# CY8C5888LTI_LP097 register map
File version: 0.1
CY8C58LP
Registers are 8-bit, read-write, no defined reset value unless marked. A register's access mark holds for its fields unless they carry their own. Offsets are from the block's base; lines under a group give offsets from that group; [hi:lo] are bit positions; {n}, {i} and the like mark numbered series; 'fields as' and 'values as' point back to an identical list; <NAME> marks a mode.

## Memory map
0x00000000 QuadDec_1
0x00000000 QuadDec_1_Cnt8
0x00000000 QuadDec_2
0x00000000 QuadDec_2_Cnt8
0x00000000 TimeOutResetReg
0x00000000 LightSens2_TimeOut
0x00000000 LightSens1_TimeOut

## QuadDec_1
Base 0x00000000
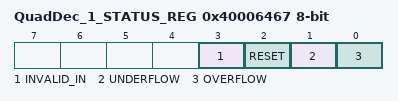
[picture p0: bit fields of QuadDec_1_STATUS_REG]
0x40006467 QuadDec_1_STATUS_REG — Quadrature Decoder Status Register
  [3] INVALID_IN ro — Invalid state transition on the A and B inputs
  [2] RESET ro — Counter Reset due index
  [1] UNDERFLOW ro — Counter underflow
  [0] OVERFLOW ro — Counter overflow
0x40006506 QuadDec_1_Cnt8_COUNTER — Counter value

## QuadDec_1_Cnt8
Base 0x00000000; alternate view of QuadDec_1
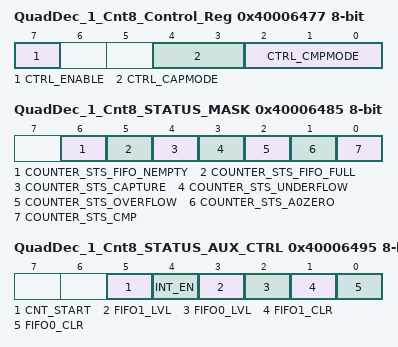
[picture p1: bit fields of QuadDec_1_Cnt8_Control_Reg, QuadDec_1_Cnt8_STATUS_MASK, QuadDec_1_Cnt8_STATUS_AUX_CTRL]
0x40006477 QuadDec_1_Cnt8_Control_Reg — UDB Control Register - Assigned Control Register Value
  [7] CTRL_ENABLE — Enable Counter
  [4:3] CTRL_CAPMODE — Capture mode
  [2:0] CTRL_CMPMODE — Compare mode
0x40006485 QuadDec_1_Cnt8_STATUS_MASK — UDB Status bits Interrupt Mask Enable Register
  [6] COUNTER_STS_FIFO_NEMPTY — FIFO Not Empty Status
  [5] COUNTER_STS_FIFO_FULL — FIFO Full Status
  [4] COUNTER_STS_CAPTURE — Capture Status
  [3] COUNTER_STS_UNDERFLOW — Underflow status
  [2] COUNTER_STS_OVERFLOW — Overflow status
  [1] COUNTER_STS_A0ZERO — A0 Zero ouput status
  [0] COUNTER_STS_CMP — Compare output status
0x40006495 QuadDec_1_Cnt8_STATUS_AUX_CTRL — UDB Auxilliary Control Register
  [5] CNT_START — FIFO0 clear
    0=E_CNT_START0 (Disable counter); 1=E_CNT_START1 (Enable counter)
  [4] INT_EN
    0=E_INT_EN0 (Interrupt disabled); 1=E_INT_EN1 (Interrupt enabled)
  [3] FIFO1_LVL — FIFO level
    0=E_FIFO_LVL_0 (FIFO LVL: input mode: FIFO not full; output mode: FIFO not empty); 1=E_FIFO_LVL_1 (FIFO LVL: input mode: FIFO at least 1/2 empty; output mode: FIFO at least 1/2 full)
  [2] FIFO0_LVL — FIFO level
    values as FIFO1_LVL
  [1] FIFO1_CLR — FIFO1 clear
    0=E_FIFO_CLR_0 (Normal FIFO operation); 1=E_FIFO_CLR_1 (Clear FIFO state)
  [0] FIFO0_CLR — FIFO0 clear
    values as FIFO1_CLR
0x40006506 QuadDec_1_Cnt8_COUNTER — UDB.A0 - Current Counter Value
0x40006526 QuadDec_1_Cnt8_PERIOD — UDB.D0 - Assigned Period
0x40006536 QuadDec_1_Cnt8_COMPARE — UDB.D1 - Assigned Compare Value

## QuadDec_2
Base 0x00000000
0x40006400 QuadDec_2_Cnt8_COUNTER — Counter value
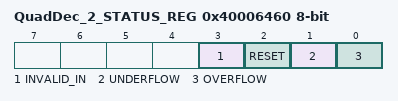
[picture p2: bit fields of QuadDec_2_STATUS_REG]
0x40006460 QuadDec_2_STATUS_REG — Quadrature Decoder Status Register
  [3] INVALID_IN ro — Invalid state transition on the A and B inputs
  [2] RESET ro — Counter Reset due index
  [1] UNDERFLOW ro — Counter underflow
  [0] OVERFLOW ro — Counter overflow

## QuadDec_2_Cnt8
Base 0x00000000; alternate view of QuadDec_2
0x40006400 QuadDec_2_Cnt8_COUNTER — UDB.A0 - Current Counter Value
0x40006420 QuadDec_2_Cnt8_PERIOD — UDB.D0 - Assigned Period
0x40006430 QuadDec_2_Cnt8_COMPARE — UDB.D1 - Assigned Compare Value
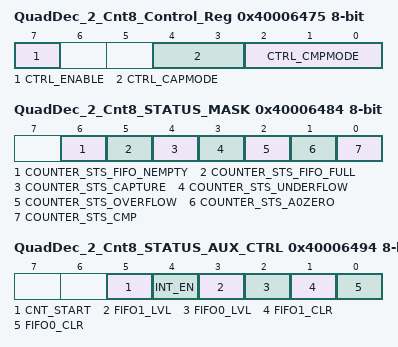
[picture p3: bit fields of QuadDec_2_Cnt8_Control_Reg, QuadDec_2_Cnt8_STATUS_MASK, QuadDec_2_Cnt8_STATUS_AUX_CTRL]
0x40006475 QuadDec_2_Cnt8_Control_Reg — UDB Control Register - Assigned Control Register Value
  [7] CTRL_ENABLE — Enable Counter
  [4:3] CTRL_CAPMODE — Capture mode
  [2:0] CTRL_CMPMODE — Compare mode
0x40006484 QuadDec_2_Cnt8_STATUS_MASK — UDB Status bits Interrupt Mask Enable Register
  [6] COUNTER_STS_FIFO_NEMPTY — FIFO Not Empty Status
  [5] COUNTER_STS_FIFO_FULL — FIFO Full Status
  [4] COUNTER_STS_CAPTURE — Capture Status
  [3] COUNTER_STS_UNDERFLOW — Underflow status
  [2] COUNTER_STS_OVERFLOW — Overflow status
  [1] COUNTER_STS_A0ZERO — A0 Zero ouput status
  [0] COUNTER_STS_CMP — Compare output status
0x40006494 QuadDec_2_Cnt8_STATUS_AUX_CTRL — UDB Auxilliary Control Register
  [5] CNT_START — FIFO0 clear
    0=E_CNT_START0 (Disable counter); 1=E_CNT_START1 (Enable counter)
  [4] INT_EN
    0=E_INT_EN0 (Interrupt disabled); 1=E_INT_EN1 (Interrupt enabled)
  [3] FIFO1_LVL — FIFO level
    0=E_FIFO_LVL_0 (FIFO LVL: input mode: FIFO not full; output mode: FIFO not empty); 1=E_FIFO_LVL_1 (FIFO LVL: input mode: FIFO at least 1/2 empty; output mode: FIFO at least 1/2 full)
  [2] FIFO0_LVL — FIFO level
    values as FIFO1_LVL
  [1] FIFO1_CLR — FIFO1 clear
    0=E_FIFO_CLR_0 (Normal FIFO operation); 1=E_FIFO_CLR_1 (Clear FIFO state)
  [0] FIFO0_CLR — FIFO0 clear
    values as FIFO1_CLR
